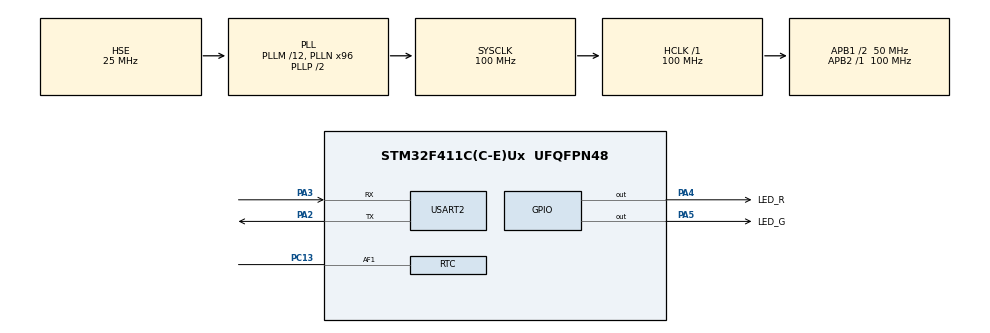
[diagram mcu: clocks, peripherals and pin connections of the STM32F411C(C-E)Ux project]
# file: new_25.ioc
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FREERTOS.Queues01=queue_input_to_uart,10,uint32_t,0,Dynamic,NULL,NULL;queue_uart_to_output,10,uint32_t,0,Dynamic,NULL,NULL;queue_output_to_input,10,uint32_t,0,Dynamic,NULL,NULL
FREERTOS.Tasks01=task_input,32,128,start_task_input,Default,NULL,Dynamic,NULL,NULL;task_uart,24,128,start_task_uart,Default,NULL,Dynamic,NULL,NULL;task_output,24,128,start_task_output,Default,NULL,Dynamic,NULL,NULL
Mcu.Family=STM32F4
Mcu.Name=STM32F411C(C-E)Ux
Mcu.Package=UFQFPN48
NVIC.PriorityGroup=NVIC_PRIORITYGROUP_4
NVIC.RTC_WKUP_IRQn=true\:6\:0\:true\:false\:true\:true\:true\:true\:true
NVIC.TIM4_IRQn=true\:15\:0\:false\:false\:true\:false\:false\:true\:true
NVIC.TimeBase=TIM4_IRQn
NVIC.TimeBaseIP=TIM4
NVIC.USART2_IRQn=true\:5\:0\:false\:false\:true\:true\:true\:true\:true
PA13.Mode=Serial_Wire
PA13.Signal=SYS_JTMS-SWDIO
PA14.Mode=Serial_Wire
PA14.Signal=SYS_JTCK-SWCLK
PA2.Mode=Asynchronous
PA2.Signal=USART2_TX
PA3.Mode=Asynchronous
PA3.Signal=USART2_RX
PA4.GPIO_Label=LED_R
PA4.GPIO_Speed=GPIO_SPEED_FREQ_VERY_HIGH
PA4.Signal=GPIO_Output
PA5.GPIO_Label=LED_G
PA5.GPIO_Speed=GPIO_SPEED_FREQ_VERY_HIGH
PA5.Signal=GPIO_Output
PC13-ANTI_TAMP.Mode=WakeUpAF1
PC13-ANTI_TAMP.Signal=RTC_AF1
PC14-OSC32_IN.Mode=LSE-External-Oscillator
PC14-OSC32_IN.Signal=RCC_OSC32_IN
PC15-OSC32_OUT.Mode=LSE-External-Oscillator
PC15-OSC32_OUT.Signal=RCC_OSC32_OUT
PH0\ -\ OSC_IN.Mode=HSE-External-Oscillator
PH0\ -\ OSC_IN.Signal=RCC_OSC_IN
PH1\ -\ OSC_OUT.Mode=HSE-External-Oscillator
PH1\ -\ OSC_OUT.Signal=RCC_OSC_OUT
ProjectManager.HeapSize=0x200
ProjectManager.StackSize=0x400
ProjectManager.TargetToolchain=MDK-ARM V5.32
RCC.48MHZClocksFreq_Value=50000000
RCC.AHBFreq_Value=100000000
RCC.APB1CLKDivider=RCC_HCLK_DIV2
RCC.APB1Freq_Value=50000000
RCC.APB1TimFreq_Value=100000000
RCC.APB2Freq_Value=100000000
RCC.APB2TimFreq_Value=100000000
RCC.CortexFreq_Value=100000000
RCC.HCLKFreq_Value=100000000
RCC.HSE_VALUE=25000000
RCC.HSI_VALUE=16000000
RCC.PLLM=12
RCC.PLLN=96
RCC.PLLSourceVirtual=RCC_PLLSOURCE_HSE
RCC.RCC_RTC_Clock_Source=RCC_RTCCLKSOURCE_LSE
RCC.RCC_RTC_Clock_SourceVirtual=RCC_RTCCLKSOURCE_LSE
RCC.SYSCLKFreq_VALUE=100000000
RCC.SYSCLKSource=RCC_SYSCLKSOURCE_PLLCLK
RCC.VCOOutputFreq_Value=200000000
RTC.Alarm=RTC_ALARM_A
RTC.AlarmDateWeekDaySel=RTC_ALARMDATEWEEKDAYSEL_DATE
RTC.AlarmMaskDateWeekDay=RTC_ALARMMASK_DATEWEEKDAY
RTC.AlarmMaskDateWeekDay_B=RTC_ALARMMASK_DATEWEEKDAY
RTC.AlarmMaskHours=RTC_ALARMMASK_HOURS
RTC.AlarmMaskHours_B=RTC_ALARMMASK_HOURS
RTC.AlarmMaskMinutes_B=RTC_ALARMMASK_MINUTES
RTC.Alarm_B=RTC_ALARM_B
RTC.Date=8
RTC.Format=RTC_FORMAT_BIN
RTC.Hours=7
RTC.Minutes=15
RTC.Minutes_A=16
RTC.Month=RTC_MONTH_NOVEMBER
RTC.OutPutType=RTC_OUTPUT_TYPE_OPENDRAIN
RTC.Seconds=10
RTC.Seconds_A=5
RTC.Seconds_B=30
RTC.WakeUpClock=RTC_WAKEUPCLOCK_CK_SPRE_16BITS
RTC.WeekDay=RTC_WEEKDAY_FRIDAY
RTC.Year=24
USART2.VirtualMode=VM_ASYNC
VP_FREERTOS_VS_CMSIS_V2.Mode=CMSIS_V2
VP_RTC_VS_RTC_Activate.Mode=RTC_Enabled
VP_RTC_VS_RTC_Alarm_A_Intern.Mode=Alarm A
VP_RTC_VS_RTC_Alarm_B_Intern.Mode=Alarm B
VP_RTC_VS_RTC_Calendar.Mode=RTC_Calendar
VP_SYS_VS_tim4.Mode=TIM4
board=custom

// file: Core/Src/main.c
/* USER CODE BEGIN Header */
/**
  ******************************************************************************
  * @file           : main.c
  * @brief          : Main program body
  ******************************************************************************
  * @attention
  *
  * Copyright (c) 2024 STMicroelectronics.
  * All rights reserved.
  *
  * This software is licensed under terms that can be found in the LICENSE file
  * in the root directory of this software component.
  * If no LICENSE file comes with this software, it is provided AS-IS.
  *
  ******************************************************************************
  */
/* USER CODE END Header */
#include "main.h"
#include "cmsis_os.h"
#include "rtc.h"
#include "usart.h"
#include "gpio.h"

void SystemClock_Config(void);
void MX_FREERTOS_Init(void);

int main(void)
{

  /* MCU Configuration--------------------------------------------------------*/

  /* Reset of all peripherals, Initializes the Flash interface and the Systick. */
  HAL_Init();

  /* Configure the system clock */
  SystemClock_Config();

  /* Initialize all configured peripherals */
  MX_GPIO_Init();
  MX_USART2_UART_Init();
  MX_RTC_Init();

  /* Init scheduler */
  osKernelInitialize();

  /* Call init function for freertos objects (in cmsis_os2.c) */
  MX_FREERTOS_Init();

  /* Start scheduler */
  osKernelStart();

  /* We should never get here as control is now taken by the scheduler */

  /* Infinite loop */
  while (1)
  {

  }
}

void SystemClock_Config(void)
{
  RCC_OscInitTypeDef RCC_OscInitStruct = {0};
  RCC_ClkInitTypeDef RCC_ClkInitStruct = {0};

  /** Configure the main internal regulator output voltage
  */
  __HAL_RCC_PWR_CLK_ENABLE();
  __HAL_PWR_VOLTAGESCALING_CONFIG(PWR_REGULATOR_VOLTAGE_SCALE1);

  /** Initializes the RCC Oscillators according to the specified parameters
  * in the RCC_OscInitTypeDef structure.
  */
  RCC_OscInitStruct.OscillatorType = RCC_OSCILLATORTYPE_HSE|RCC_OSCILLATORTYPE_LSE;
  RCC_OscInitStruct.HSEState = RCC_HSE_ON;
  RCC_OscInitStruct.LSEState = RCC_LSE_ON;
  RCC_OscInitStruct.PLL.PLLState = RCC_PLL_ON;
  RCC_OscInitStruct.PLL.PLLSource = RCC_PLLSOURCE_HSE;
  RCC_OscInitStruct.PLL.PLLM = 12;
  RCC_OscInitStruct.PLL.PLLN = 96;
  RCC_OscInitStruct.PLL.PLLP = RCC_PLLP_DIV2;
  RCC_OscInitStruct.PLL.PLLQ = 4;
  if (HAL_RCC_OscConfig(&RCC_OscInitStruct) != HAL_OK)
  {
    Error_Handler();
  }

  /** Initializes the CPU, AHB and APB buses clocks
  */
  RCC_ClkInitStruct.ClockType = RCC_CLOCKTYPE_HCLK|RCC_CLOCKTYPE_SYSCLK
                              |RCC_CLOCKTYPE_PCLK1|RCC_CLOCKTYPE_PCLK2;
  RCC_ClkInitStruct.SYSCLKSource = RCC_SYSCLKSOURCE_PLLCLK;
  RCC_ClkInitStruct.AHBCLKDivider = RCC_SYSCLK_DIV1;
  RCC_ClkInitStruct.APB1CLKDivider = RCC_HCLK_DIV2;
  RCC_ClkInitStruct.APB2CLKDivider = RCC_HCLK_DIV1;

  if (HAL_RCC_ClockConfig(&RCC_ClkInitStruct, FLASH_LATENCY_3) != HAL_OK)
  {
    Error_Handler();
  }
}

void HAL_TIM_PeriodElapsedCallback(TIM_HandleTypeDef *htim)
{
  if (htim->Instance == TIM4) {
    HAL_IncTick();
  }
}

void Error_Handler(void)
{
  __disable_irq();
  while (1)
  {
  }
}

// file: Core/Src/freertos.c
/* USER CODE BEGIN Header */
/**
  ******************************************************************************
  * File Name          : freertos.c
  * Description        : Code for freertos applications
  ******************************************************************************
  * @attention
  *
  * Copyright (c) 2024 STMicroelectronics.
  * All rights reserved.
  *
  * This software is licensed under terms that can be found in the LICENSE file
  * in the root directory of this software component.
  * If no LICENSE file comes with this software, it is provided AS-IS.
  *
  ******************************************************************************
  */
/* USER CODE END Header */

/* USER CODE BEGIN Includes */
#include "self.h"
/* USER CODE END Includes */

/* USER CODE BEGIN Variables */
uint8_t rx_buffer[BUFFER_LENGTH];
/* USER CODE END Variables */
/* Definitions for task_input */
osThreadId_t task_inputHandle;
const osThreadAttr_t task_input_attributes = {
  .name = "task_input",
  .stack_size = 128 * 4,
  .priority = (osPriority_t) osPriorityAboveNormal,
};
/* Definitions for task_uart */
osThreadId_t task_uartHandle;
const osThreadAttr_t task_uart_attributes = {
  .name = "task_uart",
  .stack_size = 128 * 4,
  .priority = (osPriority_t) osPriorityNormal,
};
/* Definitions for task_output */
osThreadId_t task_outputHandle;
const osThreadAttr_t task_output_attributes = {
  .name = "task_output",
  .stack_size = 128 * 4,
  .priority = (osPriority_t) osPriorityNormal,
};
/* Definitions for queue_input_to_uart */
osMessageQueueId_t queue_input_to_uartHandle;
const osMessageQueueAttr_t queue_input_to_uart_attributes = {
  .name = "queue_input_to_uart"
};
/* Definitions for queue_uart_to_output */
osMessageQueueId_t queue_uart_to_outputHandle;
const osMessageQueueAttr_t queue_uart_to_output_attributes = {
  .name = "queue_uart_to_output"
};
/* Definitions for queue_output_to_input */
osMessageQueueId_t queue_output_to_inputHandle;
const osMessageQueueAttr_t queue_output_to_input_attributes = {
  .name = "queue_output_to_input"
};

void start_task_input(void *argument);
void start_task_uart(void *argument);
void start_task_output(void *argument);

void MX_FREERTOS_Init(void); /* (MISRA C 2004 rule 8.1) */

void MX_FREERTOS_Init(void) {

  /* Create the queue(s) */
  /* creation of queue_input_to_uart */
  queue_input_to_uartHandle = osMessageQueueNew (10, sizeof(uint32_t), &queue_input_to_uart_attributes);

  /* creation of queue_uart_to_output */
  queue_uart_to_outputHandle = osMessageQueueNew (10, sizeof(uint32_t), &queue_uart_to_output_attributes);

  /* creation of queue_output_to_input */
  queue_output_to_inputHandle = osMessageQueueNew (10, sizeof(uint32_t), &queue_output_to_input_attributes);

  /* Create the thread(s) */
  /* creation of task_input */
  task_inputHandle = osThreadNew(start_task_input, NULL, &task_input_attributes);

  /* creation of task_uart */
  task_uartHandle = osThreadNew(start_task_uart, NULL, &task_uart_attributes);

  /* creation of task_output */
  task_outputHandle = osThreadNew(start_task_output, NULL, &task_output_attributes);

}

void start_task_input(void *argument)
{
  /* USER CODE BEGIN start_task_input */
  /* Infinite loop */
  for(;;)
  {
    vTaskDelay(2000);
  }
  /* USER CODE END start_task_input */
}

void start_task_uart(void *argument)
{
  /* USER CODE BEGIN start_task_uart */
  HAL_UART_Transmit_IT(&huart2, (uint8_t *)"start\r\n", strlen("start\r\n"));
  HAL_UART_Receive_IT(&huart2, (uint8_t *) rx_buffer, 30);
  /* Infinite loop */
  for(;;)
  {
    vTaskDelay(1000);
  }
  /* USER CODE END start_task_uart */
}

void start_task_output(void *argument)
{
  /* USER CODE BEGIN start_task_output */
  /* Infinite loop */
  for(;;)
  {
    vTaskDelay(3000);
  }
  /* USER CODE END start_task_output */
}
